# RS1xxxx register map
Vendor: Silicon Lab Inc.; Series: ARMCM4; File version: 1.2
CPU: CM4 r1p0, little endian, MPU, FPU, 6 interrupt priority bits
Registers are 32-bit, read-write, reset 0x0 unless marked. A register's access mark holds for its fields unless they carry their own. Offsets are from the block's base; [hi:lo] are bit positions; {n}, {i} and the like mark numbered series.

## MCU_FSM — This is explain the Sleep FSM registers.
Base 0x24048100
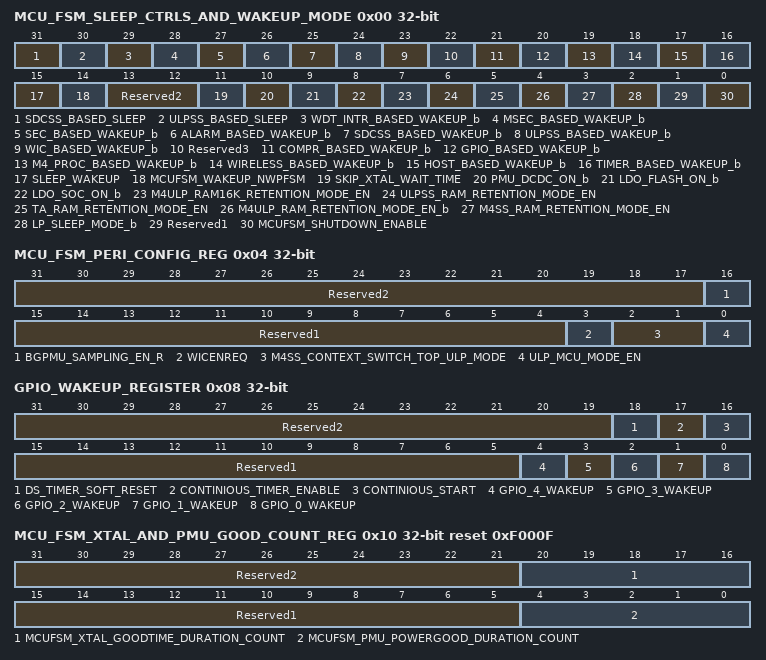
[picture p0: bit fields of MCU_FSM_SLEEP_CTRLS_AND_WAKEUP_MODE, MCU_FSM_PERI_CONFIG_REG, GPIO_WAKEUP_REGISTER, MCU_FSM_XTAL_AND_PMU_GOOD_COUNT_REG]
0x00 MCU_FSM_SLEEP_CTRLS_AND_WAKEUP_MODE — Sleep Control Signals and Wakeup source selection
  [31] SDCSS_BASED_SLEEP — SDCSS initiated DeepSleep.
  [30] ULPSS_BASED_SLEEP — ULPSS initiated DeepSleep.
  [29] WDT_INTR_BASED_WAKEUP_b — Millisecond Pulse Based wakeup
  [28] MSEC_BASED_WAKEUP_b — Millisecond Pulse Based wakeup
  [27] SEC_BASED_WAKEUP_b — Second Pulse Based wakeup
  [26] ALARM_BASED_WAKEUP_b — Alarm Based wakeup
  [25] SDCSS_BASED_WAKEUP_b — Sensor Data collector based wakeup
  [24] ULPSS_BASED_WAKEUP_b — ULPSS peripheral based wakeup
  [23] WIC_BASED_WAKEUP_b — WIC based wakeup mask
  [22] Reserved3 — It is recommended to write these bits to 0.
  [21] COMPR_BASED_WAKEUP_b — compartor based wakeup enable, either of any 6 comparator interrupts
  [20] GPIO_BASED_WAKEUP_b — wakeup on gpio interrupt enable based in configuration in GPIO WAKEUP REGISTER
  [19] M4_PROC_BASED_WAKEUP_b — wakeup based on m4 processor enable
  [18] WIRELESS_BASED_WAKEUP_b — wireless based wakeup enable
  [17] HOST_BASED_WAKEUP_b — host based wakeup enable
  [16] TIMER_BASED_WAKEUP_b — wakeup enable after deep sleep counter elapses
  [15] SLEEP_WAKEUP — Wakeup indication from Processor
  [14] MCUFSM_WAKEUP_NWPFSM — When Set, mcufsm wakeup enable will wakeup both NWP FSM and MCU FSM.Clear this BIT if this feature is not required..
  [13:12] Reserved2 — It is recommended to write these bits to 0.
  [11] SKIP_XTAL_WAIT_TIME — 1 : Skips Xtal Good Delay wait time.
  [10] PMU_DCDC_ON_b — 1: PMU DCDC(BUCK) ON,0: PMU DCDC(BUCK) OFF.
  [9] LDO_FLASH_ON_b — ON flash ldo during deep sleep
  [8] LDO_SOC_ON_b — ON ldo soc during deep sleep
  [7] M4ULP_RAM16K_RETENTION_MODE_EN — To enable retention mode for m4ulp 16k RAM
  [6] ULPSS_RAM_RETENTION_MODE_EN — RAM retention enable for ulpss ram during deep sleep
  [5] TA_RAM_RETENTION_MODE_EN — RAM retention enable for ta ram during deep sleep
  [4] M4ULP_RAM_RETENTION_MODE_EN_b — RAM retention enable for ULP M4 ram during deep sleep
  [3] M4SS_RAM_RETENTION_MODE_EN — shutdown enable pulse.
  [2] LP_SLEEP_MODE_b — setting this bit enables retention of TASS-RAM, M4SS-RAM in PS2 Active/Sleep state
    0=disable (Writing 1 to this enables Retention during sleep); 1=enable (Writing 1 to this enables Retention during sleep)
  [1] Reserved1 — It is recommended to write these bits to 0.
  [0] MCUFSM_SHUTDOWN_ENABLE — shutdown enable pulse.
0x04 MCU_FSM_PERI_CONFIG_REG — Configuration for Ultra Low-Power Mode of the processor (PS2 State)
  [31:17] Reserved2 — It is recommended to write these bits to 0.
  [16] BGPMU_SAMPLING_EN_R — Controls the mode of Band-Gap for DC-DC 1.35 during PS2 state.
    0=disable (Writing 0 to this disables sampling mode of Band-Gap. This is described in Power Management Section.); 1=enable (Writing 1 to this enables sampling mode of Band-Gap. This is described in Power Management Section.)
  [15:4] Reserved1 — It is recommended to write these bits to 0.
  [3] WICENREQ — Its enable or disable maximum of 32KB of LP-SRAM for operation in PS2 state
  [2:1] M4SS_CONTEXT_SWITCH_TOP_ULP_MODE — Enable functional switching for PS2-PS4/PS3 and PS4/PS3-PS2 state transitions
  [0] ULP_MCU_MODE_EN — Enables voltage switching for PS2-PS4/PS3 and PS4/PS3-PS2 state transitions.
    0=disable (Writing 0 to this disables voltage switching for PS2-PS4/PS3 state transition); 1=enable (Writing 1 to this enables voltage switching for PS4/PS3-PS2 state transition.)
0x08 GPIO_WAKEUP_REGISTER
  [31:19] Reserved2 — It is recommended to write these bits to 0.
  [18] DS_TIMER_SOFT_RESET — Enable Deep sleep timer mode continuous.
  [17] CONTINIOUS_TIMER_ENABLE — Enable Deep sleep timer mode continuous.
  [16] CONTINIOUS_START — Trigger Deep sleep timer to start counting.
  [15:5] Reserved1 — It is recommended to write these bits to 0.
  [4] GPIO_4_WAKEUP — Enable gpio 3 based wakeup
  [3] GPIO_3_WAKEUP — Enable gpio 3 based wakeup
  [2] GPIO_2_WAKEUP — Enable gpio 2 based wakeup
  [1] GPIO_1_WAKEUP — Enable gpio 1 based wakeup
  [0] GPIO_0_WAKEUP — Enable gpio 0 based wakeup.
0x0C MCU_FSM_DEEP_SLEEP_DURATION_LSB_REG — MCU FSM DEEP SLEEP DURATION LSB Register
  [31:0] MCUFSM_DEEPSLEEP_DURATION_COUNT — LSB bits of deep sleep duration counter after which system wakes up is timeout wakeup is enabled.
0x10 MCU_FSM_XTAL_AND_PMU_GOOD_COUNT_REG reset 0xF000F — MCU FSM XTAL AND PMU GOOD COUNT Register
  [31:21] Reserved2 — It is recommended to write these bits to 0.
  [20:16] MCUFSM_XTAL_GOODTIME_DURATION_COUNT — Wait Delay for XTAL GOOD Time 0 - 5us 1 - 10us.
  [15:5] Reserved1 — It is recommended to write these bits to 0.
  [4:0] MCUFSM_PMU_POWERGOOD_DURATION_COUNT — Wait Delay for PMU POWER GOOD 0 - 5us 1 - 10us 2 - 12.5us 3 - 25us 4 - 50us 5 - 75us.
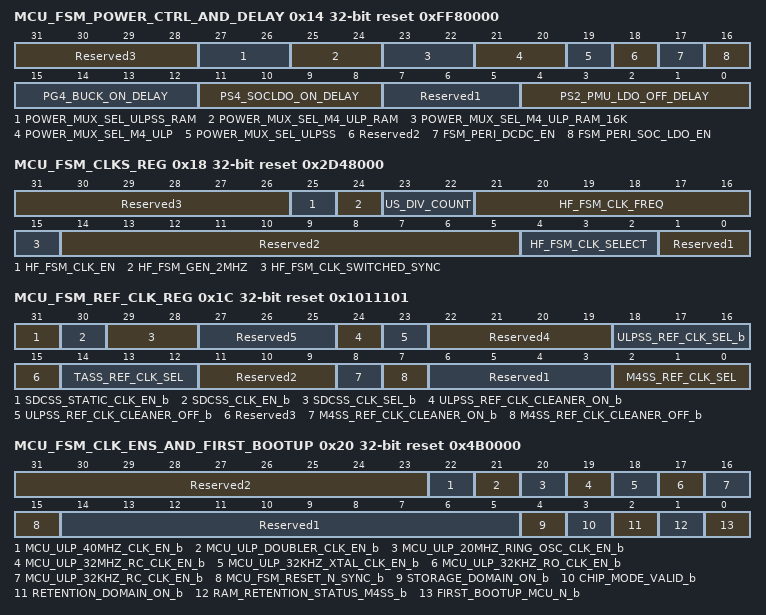
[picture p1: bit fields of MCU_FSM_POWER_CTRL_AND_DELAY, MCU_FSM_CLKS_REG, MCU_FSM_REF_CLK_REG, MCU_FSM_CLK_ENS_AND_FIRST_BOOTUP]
0x14 MCU_FSM_POWER_CTRL_AND_DELAY reset 0xFF80000 — Power Control and Delay Configuration for Ultra Low-Power Mode of the processor (PS2 State)
  [31:28] Reserved3 — It is recommended to write these bits to 0.
  [27:26] POWER_MUX_SEL_ULPSS_RAM — Select value for ULPSS RAM Power Mux.
  [25:24] POWER_MUX_SEL_M4_ULP_RAM — Select value for M4 ULP RAM Power Mux.
  [23:22] POWER_MUX_SEL_M4_ULP_RAM_16K — Select value for M4 ULP RAM 16K Power Mux
    0=LDO 0.7V; 1=DC-DC 0.95; 3=LDO SoC 1.1
  [21:20] POWER_MUX_SEL_M4_ULP — Select value for M4 ULP (Peripherals + Cortex Core )Power Mux.
    0=LDO 0.7V; 1=DC-DC 0.95; 3=LDO SoC 1.1
  [19] POWER_MUX_SEL_ULPSS — Select value for ULPSS(Peripherals) Power Mux
    0=DC-DC 0.95; 1=LDO SoC 1.1
  [18] Reserved2 — It is recommended to write these bits to 0.
  [17] FSM_PERI_DCDC_EN — Enable DCDC in Peri mode.
    0=OFF (Writing 0 to this configures DC-DC 1.35 in OFF state during PS2.); 1=ON (Writing 1 to this configures DC-DC 1.35 to ON state during PS2.)
  [16] FSM_PERI_SOC_LDO_EN — Enable SOCLDO in Peri mode.
    0=OFF (Writing 0 to this configures LDO SoC 1.1 in OFF state during PS2.); 1=ON (Writing 1 to this configures LDO SoC 1.1 to ON state during PS2.)
  [15:12] PG4_BUCK_ON_DELAY — PMU Buck Turn-ON Delay.
    0=Configure switching 50us ON time of DC-DC; 1=Configure switching 100us ON time of DC-DC; 2=Configure switching 200us ON time of DC-DC; 3=Configure switching 300us ON time of DC-DC; 4=Configure switching 400us ON time of DC-DC; 5=Configure switching 500us ON time of DC-DC; 6=Configure switching 600us ON time of DC-DC; 7=Configure switching 700us ON time of DC-DC; 8=Configure switching 800us ON time of DC-DC; 9=Configure switching 900us ON time of DC-DC; 10=Configure switching 1000us ON time of DC-DC; 11=Configure switching 1100us ON time of DC-DC; 12=Configure switching 1200us ON time of DC-DC; 13=Configure switching 1300us ON time of DC-DC; 14=Configure switching 1400us ON time of DC-DC; 15=Configure switching 1400us ON time of DC-DC
  [11:8] PS4_SOCLDO_ON_DELAY — PMU SOCLDO Turn-ON Delay.
    0=Configure switching 50us ON time of LDO Soc; 1=Configure switching 100us ON time of LDO Soc; 2=Configure switching 200us ON time of LDO Soc; 3=Configure switching 300us ON time of LDO Soc; 4=Configure switching 400us ON time of LDO Soc; 5=Configure switching 500us ON time of LDO Soc; 6=Configure switching 600us ON time of LDO Soc; 7=Configure switching 700us ON time of LDO Soc; 8=Configure switching 800us ON time of LDO Soc; 9=Configure switching 900us ON time of LDO Soc; 10=Configure switching 1000us ON time of LDO Soc; 11=Configure switching 1100us ON time of LDO Soc; 12=Configure switching 1200us ON time of LDO Soc; 13=Configure switching 1300us ON time of LDO Soc; 14=Configure switching 1400us ON time of LDO Soc; 15=Configure switching 1400us ON time of LDO Soc
  [7:5] Reserved1 — It is recommended to write these bits to 0.
  [4:0] PS2_PMU_LDO_OFF_DELAY — PMU BUCK And LDO Turn-OFF Delay.
0x18 MCU_FSM_CLKS_REG reset 0x2D48000 — MCU FSM Clocks Register
  [31:26] Reserved3 — It is recommended to write these bits to 0.
  [25] HF_FSM_CLK_EN — high frequency mcu fsm clock enable.
  [24] HF_FSM_GEN_2MHZ — Enable 2Mhz clock for FSM 1 -Enable 2Mhz option 0- Enable 4MHz option.
  [23:22] US_DIV_COUNT — One Micro second division factor. Program value to 3. If hf_fsm_gen_2mhz is 0 Program value to 1. If hf_fsm_gen_2mhz is 1.
  [21:16] HF_FSM_CLK_FREQ — High Frequency Source Clock value in MHz.
  [15] HF_FSM_CLK_SWITCHED_SYNC — If high freq fsm clock select is modified.
  [14:5] Reserved2 — It is recommended to write these bits to 0.
  [4:2] HF_FSM_CLK_SELECT — Disable signal for m4ss reference clock.
  [1:0] Reserved1 — It is recommended to write these bits to 0.
0x1C MCU_FSM_REF_CLK_REG reset 0x1011101 — MCU FSM Clocks Register
  [31] SDCSS_STATIC_CLK_EN_b — To enable static clk for sensor data collector subsystem
  [30] SDCSS_CLK_EN_b — To enable dynamic clock for sdcss
  [29:28] SDCSS_CLK_SEL_b — select between RC / RO 32KHz clk in sdcss 01 - 32MHz RC Clock 10- 20MHz RO Clock.
  [27:25] Reserved5 — It is recommended to write these bits to 0.
  [24] ULPSS_REF_CLK_CLEANER_ON_b — Clock cleaner Off signal for ulpss ref clock.
  [23] ULPSS_REF_CLK_CLEANER_OFF_b — Clock cleaner Off signal for ulpss ref clock.
  [22:19] Reserved4 — It is recommended to write these bits to 0.
  [18:16] ULPSS_REF_CLK_SEL_b — Dynamic Reference Clock Mux select of TASS controlled by M4. 0 : Clock will be gated at dynamic mux output of TASS 1 : ulp_32mhz_rc_byp_clk 2 : ulp_32mhz_rc_clk 3 : rf_ref_clk 4 : mems_ref_clk 5 : ulp_20mhz_ringosc_clk 6 : ref_byp_clk to TASS.
  [15] Reserved3 — It is recommended to write these bits to 0.
  [14:12] TASS_REF_CLK_SEL — Dynamic Reference Clock Mux select of TASS controlled by M4. 0 : Clock will be gated at dynamic mux output of TASS 1 : ulp_32mhz_rc_byp_clk 2 : ulp_32mhz_rc_clk 3 : rf_ref_clk 4 : mems_ref_clk 5 : ulp_20mhz_ringosc_clk 6 : ref_byp_clk to TASS.
  [11:9] Reserved2 — It is recommended to write these bits to 0.
  [8] M4SS_REF_CLK_CLEANER_ON_b — Enable clk cleaner for m4ss reference clock.
  [7] M4SS_REF_CLK_CLEANER_OFF_b — Disable signal for m4ss reference clock.
  [6:3] Reserved1 — It is recommended to write these bits to 0.
  [2:0] M4SS_REF_CLK_SEL — Dynamic Reference Clock Mux select of M4SS 0 - Clock will be gated at dynamic mux output of M4SS 1 - ulp_32mhz_rc_byp_clk 2 - ulp_32mhz_rc_clk 3 - rf_ref_clk 4 - mems_ref_clk 5 - ulp_20mhz_ringosc_clk 6 - ulp_doubler_clk 7 - ref_byp_clk to TASS.
0x20 MCU_FSM_CLK_ENS_AND_FIRST_BOOTUP reset 0x4B0000 — MCU FSM And First Bootup
  [31:23] Reserved2 — It is recommended to write these bits to 0.
  [22] MCU_ULP_40MHZ_CLK_EN_b — Enables 40MHz XTAL clock.
  [21] MCU_ULP_DOUBLER_CLK_EN_b — Enables ULP Doubler Clock.
  [20] MCU_ULP_20MHZ_RING_OSC_CLK_EN_b — Enables ULP 20mhz RO Clock.
  [19] MCU_ULP_32MHZ_RC_CLK_EN_b — Enables ULP 32MHz RC Clock.
  [18] MCU_ULP_32KHZ_XTAL_CLK_EN_b — Enables ULP 32KHz Xtal Clock.
  [17] MCU_ULP_32KHZ_RO_CLK_EN_b — Enables ULP 32KHz RO Clock.
  [16] MCU_ULP_32KHZ_RC_CLK_EN_b — Enables ULP 32KHz Rc Clock.
  [15] MCU_FSM_RESET_N_SYNC_b — Indicated MCU FSM is out of reset. 1 : Indicated MCU FSM is out of reset 0 : Indicated MCU FSM is in reset.
  [14:5] Reserved1 — It is recommended to write these bits to 0.
  [4] STORAGE_DOMAIN_ON_b — Indicates to S/W that MCU Data Storage 1 domain is ON. 1 - Domain is ON. 0 - Domain is OFF..
  [3] CHIP_MODE_VALID_b — Indicates to S/W that ChipMode programming are valid and need not read EFUSE. 1 - ChipMode are Valid. 0 - ChipModes are invalid.
  [2] RETENTION_DOMAIN_ON_b — Indicates to S/W that Retention domain is ON. 1 - Domain is ON. 0 - Domain is OFF..
  [1] RAM_RETENTION_STATUS_M4SS_b ro — Indicates to S/W that RAM's were in retention mode during Sleep time. 1 - RAM are in retention mode during sleep. 0 - RAM are not in retention mode during sleep.Domain is OFF..
  [0] FIRST_BOOTUP_MCU_N_b — Indication for S/W to distinguish b/w First Power or ULP wakeup.S/W need to set this Bit after first power ..
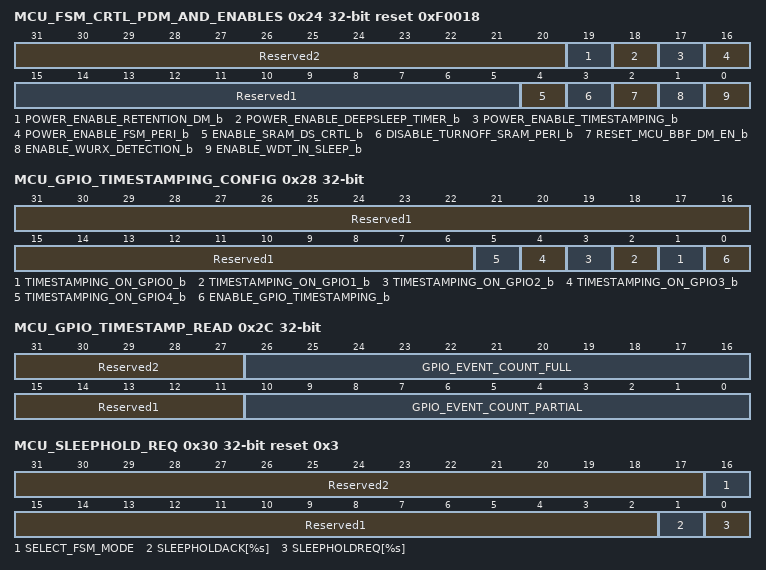
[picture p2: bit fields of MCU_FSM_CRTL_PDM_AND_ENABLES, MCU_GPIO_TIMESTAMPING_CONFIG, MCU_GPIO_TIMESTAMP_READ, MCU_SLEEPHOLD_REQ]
0x24 MCU_FSM_CRTL_PDM_AND_ENABLES reset 0xF0018 — Power Domains Controlled by Sleep FSM.
  [31:20] Reserved2 — It is recommended to write these bits to 0.
  [19] POWER_ENABLE_RETENTION_DM_b — Its enable or disable Power to Retention Flops during SHIP state.These Flops are used for storing Chip Configuration.
    0=disable (Writing 0 to this disables Power to Retention Flops during SHIP state. These Flops are used for storing Chip Configuration.); 1=enable (Writing 1 to this enables Power to Retention Flops during SHIP state. These Flops are used for storing Chip Configuration.)
  [18] POWER_ENABLE_DEEPSLEEP_TIMER_b — Its enable or disable Power to DEEP SLEEP Timer.
    0=disable (Writing 0 to this disables Power to DEEP SLEEP Timer.); 1=enable (Writing 1 to this enables Power to DEEP SLEEP Timer.)
  [17] POWER_ENABLE_TIMESTAMPING_b — Its enable or disable Power to TIMESTAMP.
    0=disable (Writing 0 to this disables Power to TIMESTAMP.); 1=enable (Writing 1 to this enables Power to TIMESTAMP.)
  [16] POWER_ENABLE_FSM_PERI_b — Its enable or disable Power to Low-Power FSM.
    0=disable (Writing 0 to this disables Power to Low-Power FSM.); 1=enable (Writing 1 to this enables Power to Low-Power FSM.)
  [15:5] Reserved1 — It is recommended to write these bits to 0.
  [4] ENABLE_SRAM_DS_CRTL_b — Enable signal for controlling Deepsleep signal of all SRAM used by M4 1- Enable SRAM Deepsleep Signal 0- Disable SRAM Deepsleep Signal.
  [3] DISABLE_TURNOFF_SRAM_PERI_b — Enable MCU SRAM periphery during Deepsleep 1 - Enable SRAM periphery during Deepsleep 0 - Disable SRAM periphery during Deepsleep.
  [2] RESET_MCU_BBF_DM_EN_b — Its enable or disable reset of Power Domain Control Battery FF's on wakeup.
    0=disable (Writing 0 to this disables reset of Power Domain Control Battery FF's on wakeup.); 1=enable (Writing 1 to this enables reset of Power Domain Control Battery FF's on wakeup)
  [1] ENABLE_WURX_DETECTION_b — Its enable or disable detection of On-Air Pattern using Wake-Fi Rx.
    0=disable (Writing 0 to this disables detection of On-Air Pattern using Wake-Fi Rx.); 1=enable (Writing 1 to this enables detection of On-Air Pattern using Wake-Fi Rx.)
  [0] ENABLE_WDT_IN_SLEEP_b — Its enable or disable WDT during Sleep/Shutdown states.
    0=disable (Writing 0 to this enables WDT during Sleep/Shutdown states.); 1=enable (Writing 1 to this enables WDT during Sleep/Shutdown states.)
0x28 MCU_GPIO_TIMESTAMPING_CONFIG
  [31:6] Reserved1 — It is recommended to write these bits to 0.
  [n+1] TIMESTAMPING_ON_GPIO{n}_b (n=0..4) — Enable GPIO time stamping on GPIO{n}.
  [0] ENABLE_GPIO_TIMESTAMPING_b — Enable GPIO time stamping Feature..
0x2C MCU_GPIO_TIMESTAMP_READ ro — MCU GPIO TIMESTAMPING READ.
  [31:27] Reserved2 — It is recommended to write these bits to 0.
  [26:16] GPIO_EVENT_COUNT_FULL — Counter value indicating number for 32MHz clock present in 1 Sleep clock (MCU FSM Clock).
  [15:11] Reserved1 — It is recommended to write these bits to 0.
  [10:0] GPIO_EVENT_COUNT_PARTIAL — Counter value indicating the duration from GPIO going high to first Sleep clock( MCU FSM Clock) posedge from GPIO going high with respect to 32MHz clock.
0x30 MCU_SLEEPHOLD_REQ reset 0x3
  [31:17] Reserved2 — It is recommended to write these bits to 0.
  [16] SELECT_FSM_MODE — Enable for selecting secondary FSM. 1 - Select Secondary FSM 0 - Select Primary FSM.
  [15:2] Reserved1 — It is recommended to write these bits to 0.
  [1] SLEEPHOLDACK[%s] ro — SLEEPHOLDACK response to SLEEPHOLDREQ.
  [0] SLEEPHOLDREQ[%s] — Sleepholdreq when enable will gate the clock to M4. 1 - Sleepholdreq is Disabled. 0 - Sleepholdreq is Enabled.
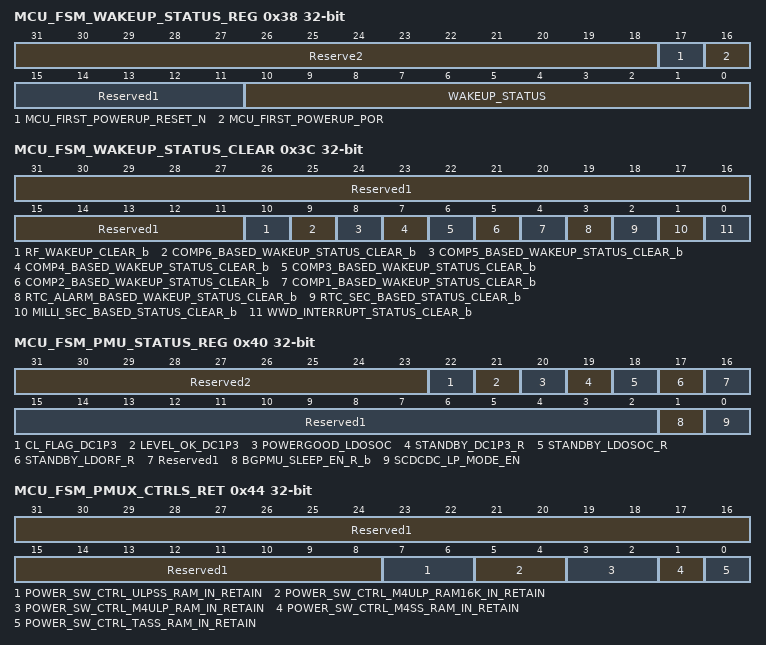
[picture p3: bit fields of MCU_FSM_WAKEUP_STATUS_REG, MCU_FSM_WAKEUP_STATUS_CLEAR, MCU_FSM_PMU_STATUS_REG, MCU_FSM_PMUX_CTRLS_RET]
0x38 MCU_FSM_WAKEUP_STATUS_REG — MCU FSM Wakeup Status Register.
  [31:18] Reserve2 — It is recommended to write these bits to 0.
  [17] MCU_FIRST_POWERUP_RESET_N — Indication to Processor that system came out of Reset.
  [16] MCU_FIRST_POWERUP_POR — Indication to Processor that system came out first power up.
  [15:11] Reserved1 — It is recommended to write these bits to 0.
  [10:0] WAKEUP_STATUS — To know the wakeup source.
0x3C MCU_FSM_WAKEUP_STATUS_CLEAR
  [31:11] Reserved1 — It is recommended to write these bits to 0.
  [10] RF_WAKEUP_CLEAR_b — To Clear WuRX status indication.
  [9] COMP6_BASED_WAKEUP_STATUS_CLEAR_b — To Clear Button-wake status indication.
  [8] COMP5_BASED_WAKEUP_STATUS_CLEAR_b — To Clear BOD Wakeup status indication.
  [7] COMP4_BASED_WAKEUP_STATUS_CLEAR_b — To Clear Comp4 wakeup (Bandgap En and VBatt Scale) status indication.
  [6] COMP3_BASED_WAKEUP_STATUS_CLEAR_b — To Clear comp3 wakeup (Analog IP1 and VBatt Scale) status indication.
  [5] COMP2_BASED_WAKEUP_STATUS_CLEAR_b — To Clear comp2 wakeup (Analog IP1 and BandGap Scale) status indication.
  [4] COMP1_BASED_WAKEUP_STATUS_CLEAR_b — To Clear comp1 wakeup (Analog IP1 and Analog IP2) status indication.
  [3] RTC_ALARM_BASED_WAKEUP_STATUS_CLEAR_b — To Clear RTC Alarm wakeup status indicaition.
  [2] RTC_SEC_BASED_STATUS_CLEAR_b — To Clear Second Tick wakeup status indication.
  [1] MILLI_SEC_BASED_STATUS_CLEAR_b — To Clear Milli-Second Wakeup status indication.
  [0] WWD_INTERRUPT_STATUS_CLEAR_b — To Clear WatchDog Interrupt status indication.
0x40 MCU_FSM_PMU_STATUS_REG — MCU FSM PMU Status Register.
  [31:23] Reserved2 — It is recommended to write these bits to 0.
  [22] CL_FLAG_DC1P3 ro — Powergood signal read for DC 1.3V.
  [21] LEVEL_OK_DC1P3 ro — Powergood signal from LDORF.
  [20] POWERGOOD_LDOSOC ro — Powergood signal from ldosoc.
  [19] STANDBY_DC1P3_R — Standby state for DC1p3.
  [18] STANDBY_LDOSOC_R — Standby state for LDO soc.
  [17] STANDBY_LDORF_R — Standby state for LDO RF.
  [16:2] Reserved1 — It is recommended to write these bits to 0.
  [1] BGPMU_SLEEP_EN_R_b — Sleep en for BG PMU.
  [0] SCDCDC_LP_MODE_EN — SCDC in LP mode.
0x44 MCU_FSM_PMUX_CTRLS_RET — MCU FSM PMUX Controls Retention.
  [31:8] Reserved1 — It is recommended to write these bits to 0.
  [7:6] POWER_SW_CTRL_ULPSS_RAM_IN_RETAIN — Select value for ULPSS RAM Power Mux In Retention mode
  [5:4] POWER_SW_CTRL_M4ULP_RAM16K_IN_RETAIN — Select value for M4ULP 16K RAM Power Mux In Retention mode
  [3:2] POWER_SW_CTRL_M4ULP_RAM_IN_RETAIN — Select value for M4ULP RAM Power Mux In Retention mode
  [1] POWER_SW_CTRL_M4SS_RAM_IN_RETAIN — Select value for M4SS RAM Power Mux In Retention mode
  [0] POWER_SW_CTRL_TASS_RAM_IN_RETAIN — Select value for TASS RAM Power Mux In Retention mode
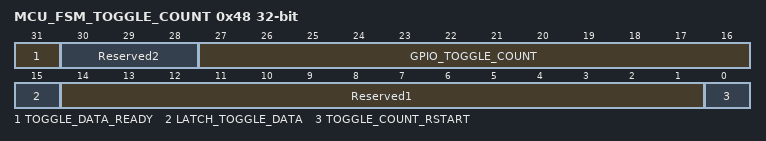
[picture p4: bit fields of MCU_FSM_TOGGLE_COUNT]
0x48 MCU_FSM_TOGGLE_COUNT
  [31] TOGGLE_DATA_READY ro — GPIO toogle data count.
  [30:28] Reserved2 — It is recommended to write these bits to 0.
  [27:16] GPIO_TOGGLE_COUNT ro — GPIO toogle data count.
  [15] LATCH_TOGGLE_DATA wo — Trigger indication to read GPIO toggle data.
  [14:1] Reserved1 — It is recommended to write these bits to 0.
  [0] TOGGLE_COUNT_RSTART wo — Start counting GIPO Toggles.
